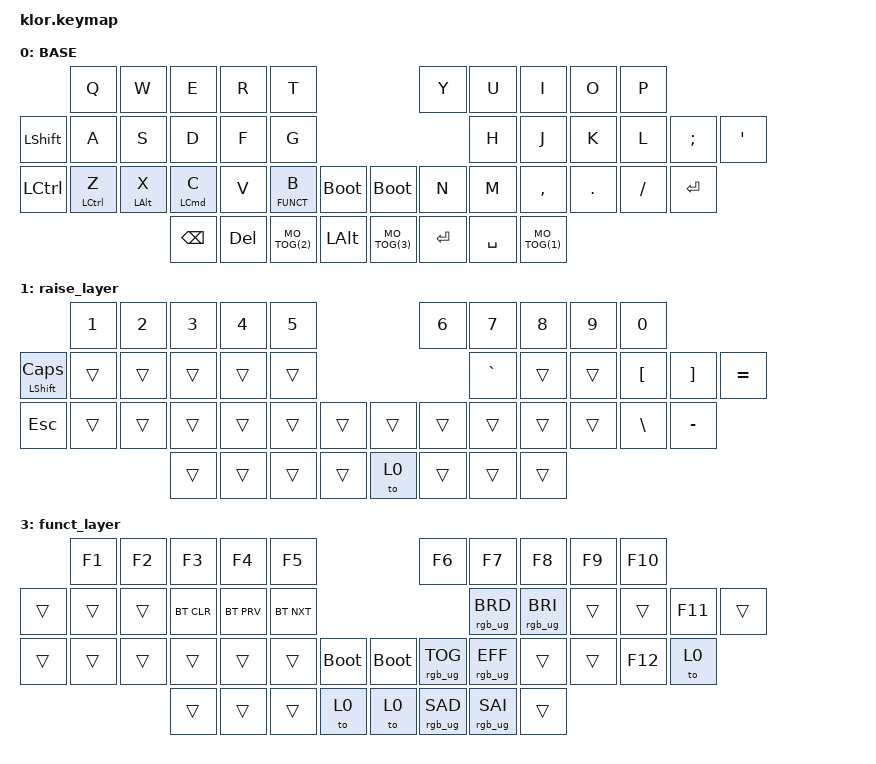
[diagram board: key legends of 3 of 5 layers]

//                               █         █    █            ▄▄▄▀▀▀▀▀▀▄▄▄        █▀▀▀▀▀▀▀▀▀▀█
//                               █        █     █          ▄▀            ▀▄      █          █
//                               █       █      █        ▄▀                ▀▄    █          █
//                               █      █       █        █                  █    █          █
//                               █     █        █       █                    █   █          █
//                               █    █         █       █                    █   █▄▄▄▄▄▄▄▄▄▄█
//                               █   █ █        █       █                    █   █      █
//                               █  █   █       █        █                  █    █       █
//                               █ █     █      █        ▀▄                ▄▀    █        █
//                               ██       █     █          ▀▄            ▄▀      █         █
//                               █         █    █▄▄▄▄▄▄▄▄    ▀▀▀▄▄▄▄▄▄▀▀▀        █          █
//
// ▄▄▄▄▄▄▄▄▄▄▄▄▄▄▄▄▄▄▄▄▄▄▄▄▄▄▄▄▄▄▄▄▄▄▄▄▄▄▄▄▄▄▄▄▄▄▄▄▄▄▄▄▄▄▄▄▄▄▄▄▄▄▄▄▄▄▄▄▄▄▄▄▄▄▄▄▄▄▄▄▄▄▄▄▄▄▄▄▄▄▄▄▄▄▄▄▄▄▄▄▄▄▄▄▄▄▄▄▄▄▄▄▄▄▄▄▄▄▄▄▄▄▄▄▄
       
#include <behaviors.dtsi>
#include <dt-bindings/zmk/keys.h>
#include <dt-bindings/zmk/bt.h>
#include <dt-bindings/zmk/outputs.h>
#include <dt-bindings/zmk/ext_power.h>
#include <dt-bindings/zmk/rgb.h>
#include <dt-bindings/zmk/backlight.h>

#define DEFAULT 0
#define RAISE   1
#define NAVIG   2
#define FUNCT   3
#define NUM     4

#define MO_TOG(layer) &mo_tog layer layer   // Macro to apply momentary-layer-on-hold/toggle-layer-on-tap to a specific layer


/ {
    behaviors {
        hm: homerow_mods {
            compatible = "zmk,behavior-hold-tap";
            label = "HOMEROW_MODS";
            #binding-cells = <2>;
            tapping-term-ms = <150>;
            quick_tap_ms = <0>;
            flavor = "tap-preferred";
            bindings =
                <&kp>,
                <&kp>;
        };
       mo_tog: behavior_mo_tog {
            compatible = "zmk,behavior-hold-tap";
            label = "mo_tog";
            #binding-cells = <2>;
            flavor = "hold-preferred";
            tapping-term-ms = <200>;
            bindings = <&mo>, <&tog>;
        };
       rgb_brightness: rgb_brightness {
            compatible = "zmk,behavior-sensor-rotate";
            label = "RGB_BRIGHTNESS";
            #sensor-binding-cells = <0>;
            bindings = <&rgb_ug RGB_BRD>, <&rgb_ug RGB_BRI>;
        };

      rgb_hue: rgb_hue {
            compatible = "zmk,behavior-sensor-rotate";
            label = "RGB_HUE";
            #sensor-binding-cells = <0>;
            bindings = <&rgb_ug RGB_HUI>, <&rgb_ug RGB_HUD>;
        };

      rgb_saturation: rgb_saturation {
            compatible = "zmk,behavior-sensor-rotate";
            label = "RGB_SATURATION";
            #sensor-binding-cells = <0>;
            bindings = <&rgb_ug RGB_SAD>, <&rgb_ug RGB_SAI>;
        };
      bt_sel: bt_sel {
            compatible = "zmk,behavior-sensor-rotate";
            label = "BT_SEL";
            #sensor-binding-cells = <0>;
            bindings = <&bt BT_NXT>, <&bt BT_PRV>;
        };
    };

combos {
            compatible = "zmk,combos";
     //layers 0
            combo_esc0 {
                timeout-ms = <50>;
                key-positions = <1 2>;
                bindings = <&kp ESC>;
                layers = <0>;
            };
            combo_tab0{
                timeout-ms = <50>;
                key-positions = <11 12>;
                bindings = <&kp TAB>;
                layers = <0>;
             };
       //BS_ENT
            combo_bsp0{
                timeout-ms = <50>;
                key-positions = <16 17>;
                bindings = <&kp BSPC>;
                layers = <0>;
            };
            combo_ent0{
                timeout-ms = <50>;
                key-positions = <17 18>;
                bindings = <&kp ENTER>;
                layers = <0>;
            };
         //Page UP_DN
             combo_pageup0{
                timeout-ms = <50>;
                key-positions = <5 6>;
                bindings = <&kp PG_UP>;
                layers = <0>;
            };
            combo_pagedown0{
                timeout-ms = <50>;
                key-positions = <27 28>;
                bindings = <&kp PG_DN>;
                layers = <0>;
            };
            
      //layers 1
         //BS_ENT
            combo_bsp1{
                timeout-ms = <50>;
                key-positions = <16 17>;
                bindings = <&kp BSPC>;
                layers = <1>;
            };
            combo_ent1{
                timeout-ms = <50>;
                key-positions = <17 18>;
                bindings = <&kp ENTER>;
                layers = <1>;
            };
          //VOLUME_UP_DOWN - BRI_UP_DN
            combo_volup1{
                timeout-ms = <50>;
                key-positions = <5 6>;
                bindings = <&kp C_VOL_UP>;
                layers = <1>;
            };
            combo_voldn1{
                timeout-ms = <50>;
                key-positions = <27 28>;
                bindings = <&kp C_VOL_DN>;
                layers = <1>;
            };
           //BRI_UP_DN
            combo_briup1{
                timeout-ms = <50>;
                key-positions = <13 14>;
                bindings = <&kp C_BRI_DN>;
                layers = <1>;
            };
            combo_bridn1{
                timeout-ms = <50>;
                key-positions = <15 16>;
                bindings = <&kp C_BRI_UP>;
                layers = <1>;
            };
  
            
            
      //layers 2
          //BS_ENT
            combo_bsp2{
                timeout-ms = <50>;
                key-positions = <16 17>;
                bindings = <&kp BSPC>;
                layers = <2>;
            };
            combo_ent2{
                timeout-ms = <50>;
                key-positions = <17 18>;
                bindings = <&kp ENTER>;
                layers = <2>;
            };
    };

    keymap {
        compatible = "zmk,keymap";

// ▄▄▄▄▄▄▄▄▄▄▄▄▄▄▄▄▄▄▄▄▄▄▄▄▄▄▄▄▄▄▄▄▄▄▄▄▄▄▄▄▄▄▄▄▄▄▄▄▄▄▄▄▄▄▄▄▄▄▄▄▄▄▄▄▄▄▄▄▄▄▄▄▄▄▄▄▄▄▄▄▄▄▄▄▄▄▄▄▄▄▄▄▄▄▄▄▄▄▄▄▄▄▄▄▄▄▄▄▄▄▄▄▄▄▄▄▄▄▄▄▄▄▄▄▄▄▄▄▄▄▄▄▄▄▄▄▄▄▄▄▄▄


                base_layer {
// ┌───────────────────────────────────────────────────────────┐
label= "BASE"                                                  ;
// └───────────────────────────────────────────────────────────┘
/*
             ┌─────────┬─────────┬─────────┬─────────┬─────────┐                    ┌─────────┬─────────┬─────────┬─────────┬─────────┐
             │    Q    │    W  {ESC}  E    │    R    │    T    │ ╭╮╭╮╭╮╭╮╭╮╭╮╭╮╭╮╭╮ │    Y  {SCU}  U    │    I    │    O    │    P    │
             ├─────────┼─────────┼─────────┼─────────┼─────────┤ │╰╯╰╯╰╯╰╯╰╯╰╯╰╯╰╯│ ├─────────┼─────────┼─────────┼─────────┼─────────┤
             │    A    │    S    │    D    │    F  {SCL}  G    ├─╯                ╰─┤    H  {SCR}  J  {BSP}  K  {ENT}  L    │    ;    │
             ├─────────┼─────────┼─────────┼─────────┼─────────┤╭────────╮╭────────╮├─────────┼─────────┼─────────┼─────────┼─────────┤
             │ (CTL)Z  │ (ALT)X  │ (CMD)C  │    V    │    B    ││  MUTE  ││PLY/PSE ││    N  {SCD}  M    │    ,    │    .    │    /    │
             └─────────┴─────────┼─────────┼─────────┼─────────┤╰────────╯╰────────╯┼─────────┼─────────┼─────────┼─────────┴─────────┘
                                 │         │ SFT*TAB │ NUM*SPC │                    │ SYM * - │ SFT * ! │         │
                                 └─────────┴─────────┴─────────┘                    └─────────┴─────────┴─────────┘ 
                                 &hm LCTRL A &hm LGUI S &hm LALT D &hm LSHIFT F
                                 */ 
   bindings = <
 //╷         ╷         ╷         ╷         ╷         ╷         ╷         ╷╷         ╷         ╷         ╷         ╷         ╷         ╷         ╷
                &kp Q     &kp W     &kp E     &kp R     &kp T                          &kp Y     &kp U     &kp I     &kp O     &kp P
    &kp LSHIFT  &kp A     &kp S     &kp D     &kp F     &kp G                          &kp H     &kp J     &kp K     &kp L     &kp SEMI  &kp SQT
    &kp LCTRL   &hm LCTRL Z   &hm LALT X   &hm LCMD C   &kp V   &lt FUNCT B   &bootloader   &bootloader   &kp N   &kp M   &kp COMMA   &kp DOT   &kp FSLH   &kp RET
                                 &kp BSPC &kp DEL  MO_TOG(2) &kp LALT   MO_TOG(3)  &kp RET   &kp SPACE  MO_TOG(1)   
                        >;
            sensor-bindings = <&bt_sel &inc_dec_kp C_VOL_UP C_VOL_DN>;
                };
// ▄▄▄▄▄▄▄▄▄▄▄▄▄▄▄▄▄▄▄▄▄▄▄▄▄▄▄▄▄▄▄▄▄▄▄▄▄▄▄▄▄▄▄▄▄▄▄▄▄▄▄▄▄▄▄▄▄▄▄▄▄▄▄▄▄▄▄▄▄▄▄▄▄▄▄▄▄▄▄▄▄▄▄▄▄▄▄▄▄▄▄▄▄▄▄▄▄▄▄▄▄▄▄▄▄▄▄▄▄▄▄▄▄▄▄▄▄▄▄▄▄▄▄▄▄▄▄▄▄▄▄▄▄▄▄▄▄▄▄▄▄▄


                raise_layer {

/*           ┌─────────┬─────────┬─────────┬─────────┬─────────┐                    ┌─────────┬─────────┬─────────┬─────────┬─────────┐
             │    1    │    2    │    3    │    4    │    5    │                    │    6    │    7    │    8    │    9    │    0    │
   ┌─────────┼─────────┼─────────┼─────────┼─────────┼─────────┤                    ├─────────┼─────────┼─────────┼─────────┼─────────┼─────────┐
   │  SCAPS  │         │         │         │         │         │                    │    `    │         │         │    [    │    ]    │    =    │
   ├─────────┼─────────┼─────────┼─────────┼─────────┼─────────┤╭────────╮╭────────╮├─────────┼─────────┼─────────┼─────────┼─────────┼─────────┤
   │   ESC   │         │         │         │         │         ││        ││        ││         │         │         │         │   \ |   │    -    │
   └─────────┴─────────┴─────────┼─────────┼─────────┼─────────┼╰────────╯╰────────╯┼─────────┼─────────┼─────────┼─────────┴─────────┴─────────┘
                                 │         │         │         │         ││   (0)   │         │         │         │  
                                 └─────────┴─────────┴─────────┴─────────┘└─────────┴─────────┴─────────┴─────────┘ */ 
 bindings = <
 //╷         ╷         ╷         ╷         ╷         ╷         ╷         ╷╷         ╷         ╷         ╷         ╷         ╷         ╷         ╷
               &kp N1   &kp N2    &kp N3    &kp N4   &kp N5                            &kp N6   &kp N7    &kp N8    &kp N9    &kp N0
    &mt LSHIFT CLCK  &trans    &trans  &trans  &trans &trans                           &kp GRAVE &trans    &trans  &kp LBKT &kp RBKT    &kp EQUAL
    &kp ESC    &trans   &trans     &trans    &trans   &trans      &trans    &trans     &trans   &trans    &trans    &trans   &kp BSLH  &kp MINUS
                                  &trans    &trans    &trans    &trans     &to 0      &trans   &trans    &trans 
                        >;
            sensor-bindings = <&inc_dec_kp C_VOL_UP C_VOL_DN>;
                };

// ▄▄▄▄▄▄▄▄▄▄▄▄▄▄▄▄▄▄▄▄▄▄▄▄▄▄▄▄▄▄▄▄▄▄▄▄▄▄▄▄▄▄▄▄▄▄▄▄▄▄▄▄▄▄▄▄▄▄▄▄▄▄▄▄▄▄▄▄▄▄▄▄▄▄▄▄▄▄▄▄▄▄▄▄▄▄▄▄▄▄▄▄▄▄▄▄▄▄▄▄▄▄▄▄▄▄▄▄▄▄▄▄▄▄▄▄▄▄▄▄▄▄▄▄▄


                navig_layer {

/*          
             ┌─────────┬─────────┬─────────┬─────────┬─────────┐                    ┌─────────┬─────────┬─────────┬─────────┬─────────┐
             │  ALLCOPY│   SAVE  │   SCRSF │  SCRS   │    +    │ ╭╮╭╮╭╮╭╮╭╮╭╮╭╮╭╮╭╮ │    6 {VOLU}  7    │    8    │    9    │    0    │
             ├─────────┼─────────┼─────────┼─────────┼─────────┤ │╰╯╰╯╰╯╰╯╰╯╰╯╰╯╰╯│ ├─────────┼─────────┼─────────┼─────────┼─────────┤
             │  UNDO   │   CUT   │   COPY  │ PASTE {BRU}  -    ├─╯                ╰─┤    ←  {BRD}  ↑  {BSP}  ↓  {ENT}  →    │    =    │
             ├─────────┼─────────┼─────────┼─────────┼─────────┤╭────────╮╭────────╮├─────────┼─────────┼─────────┼─────────┼─────────┤
             │  CTL    │   ALT   │   CMD   │   SFT   │    *    ││  MUTE  ││PLY/PSE ││    1 {VOLD}  2    │    3    │    4    │    5    │
             └─────────┴─────────┼─────────┼─────────┼─────────┤╰────────╯╰────────╯┼─────────┼─────────┼─────────┼─────────┴─────────┘
                                 │         │    /    │    ▼    │                    │    %    │    .    │         │
                                 └─────────┴─────────┴─────────┘                    └───-─────┴─────────┴─────────┘*/

 bindings = <
 //╷           ╷           ╷           ╷           ╷           ╷           ╷╷           ╷           ╷           ╷           ╷           ╷           ╷
    &kp LG(A)   &kp LG(S)   &sk LG(LS(N3))  &sk LG(LS(N4))  &kp PLUS                     &kp KP_N6   &kp KP_N7   &kp KP_N8   &kp KP_N9   &kp KP_N0
    &kp LG(Z)   &kp LG(X)   &kp LG(C)   &kp LG(V)   &kp MINUS                            &kp LEFT    &kp DOWN    &kp UP      &kp RIGHT   &kp EQUAL
    &kp LCTRL   &kp LALT    &kp LCMD    &kp LSHFT   &kp STAR    &trans        &trans     &kp N1      &kp KP_N2   &kp KP_N3   &kp KP_N4   &kp KP_N5
                            &trans      &kp SLASH   &trans                               &kp PRCNT   &kp DOT     &kp COMMA
                        >;
            sensor-bindings = <&inc_dec_kp C_VOL_UP C_VOL_DN>;
                };

// ▄▄▄▄▄▄▄▄▄▄▄▄▄▄▄▄▄▄▄▄▄▄▄▄▄▄▄▄▄▄▄▄▄▄▄▄▄▄▄▄▄▄▄▄▄▄▄▄▄▄▄▄▄▄▄▄▄▄▄▄▄▄▄▄▄▄▄▄▄▄▄▄▄▄▄▄▄▄▄▄▄▄▄▄▄▄▄▄▄▄▄▄▄▄▄▄▄▄▄▄▄▄▄▄▄▄▄▄▄▄▄▄▄▄▄▄▄▄▄▄▄▄▄▄▄


                funct_layer {

/*           ┌─────────┬─────────┬─────────┬─────────┬─────────┐                    ┌─────────┬─────────┬─────────┬─────────┬─────────┐
             │   F1    │    F2   │    F3   │    F4   │    F5   │                    │   F6    │    F7   │   F8    │   F9    │   F10   │
   ┌─────────┼─────────┼─────────┼─────────┼─────────┼─────────┤                    ├─────────┼─────────┼─────────┼─────────┼─────────┼─────────┐
   │         │         │         │ BT_CLR  | BT_PRV  │ BT_NXT  │                    │         │         │         │         │   F11   │         │
   ├─────────┼─────────┼─────────┼─────────┼─────────┼─────────┤╭────────╮╭────────╮├─────────┼─────────┼─────────┼─────────┼─────────┼─────────┤
   │         │         │         │         │         │         ││  boot  ││  boot  |│ RGB Y/N │ RGB Eff │         │         │   F12   │   (0)   |
   └─────────┴─────────┴─────────┼─────────┼─────────┼─────────┼╰────────╯╰────────╯┼─────────┼─────────┼─────────┼─────────┴─────────┴─────────┘
                                 │         │         │         │   (0)   ││   (0)   │         │         │         │  
                                 └─────────┴─────────┴─────────┴─────────┘└─────────┴─────────┴─────────┴─────────┘ */ 
 bindings = <
 //╷         ╷         ╷         ╷         ╷         ╷         ╷         ╷╷         ╷         ╷         ╷         ╷         ╷         ╷         ╷
               &kp F1    &kp F2    &kp F3    &kp F4     &kp F5                        &kp F6    &kp F7     &kp F8    &kp F9   &kp F10   
    &trans     &trans    &trans    &bt BT_CLR &bt BT_PRV &bt BT_NXT                   &rgb_ug RGB_BRD   &rgb_ug RGB_BRI    &trans    &trans    &kp F11    &trans 
    &trans     &trans    &trans    &trans    &trans   &trans &bootloader  &bootloader  &rgb_ug RGB_TOG &rgb_ug RGB_EFF &trans &trans &kp F12 &to 0    
                                   &trans  &trans     &trans &to 0     &to 0    &rgb_ug RGB_SAD   &rgb_ug RGB_SAI    &trans    
                        >;
            sensor-bindings = <&rgb_hue &rgb_brightness>;
                };
// ▄▄▄▄▄▄▄▄▄▄▄▄▄▄▄▄▄▄▄▄▄▄▄▄▄▄▄▄▄▄▄▄▄▄▄▄▄▄▄▄▄▄▄▄▄▄▄▄▄▄▄▄▄▄▄▄▄▄▄▄▄▄▄▄▄▄▄▄▄▄▄▄▄▄▄▄▄▄▄▄▄▄▄▄▄▄▄▄▄▄▄▄▄▄▄▄▄▄▄▄▄▄▄▄▄▄▄▄▄▄▄▄▄▄▄▄▄▄▄▄▄▄▄▄▄

              num_layer {
// ┌───────────────────────────────────────────────────────────┐
label= "NUM"                                                   ;
// └───────────────────────────────────────────────────────────┘
/*          
             ┌─────────┬─────────┬─────────┬─────────┬─────────┐                    ┌─────────┬─────────┬─────────┬─────────┬─────────┐
             │  ALLCOPY│   SAVE  │   SCRSF │  SCRS   │    +    │ ╭╮╭╮╭╮╭╮╭╮╭╮╭╮╭╮╭╮ │    6 {VOLU}  7    │    8    │    9    │    0    │
             ├─────────┼─────────┼─────────┼─────────┼─────────┤ │╰╯╰╯╰╯╰╯╰╯╰╯╰╯╰╯│ ├─────────┼─────────┼─────────┼─────────┼─────────┤
             │  UNDO   │   CUT   │   COPY  │ PASTE {BRU}  -    ├─╯                ╰─┤    ←  {BRD}  ↑  {BSP}  ↓  {ENT}  →    │    =    │
             ├─────────┼─────────┼─────────┼─────────┼─────────┤╭────────╮╭────────╮├─────────┼─────────┼─────────┼─────────┼─────────┤
             │  CTL    │   ALT   │   CMD   │   SFT   │    *    ││  MUTE  ││PLY/PSE ││    1 {VOLD}  2    │    3    │    4    │    5    │
             └─────────┴─────────┼─────────┼─────────┼─────────┤╰────────╯╰────────╯┼─────────┼─────────┼─────────┼─────────┴─────────┘
                                 │         │    /    │    ▼    │                    │    %    │    .    │         │
                                 └─────────┴─────────┴─────────┘                    └───-─────┴─────────┴─────────┘*/

 bindings = <
 //       ╷           ╷           ╷           ╷           ╷           ╷           ╷╷           ╷           ╷           ╷           ╷           ╷           ╷
              &kp N1      &kp N2      &kp N3      &kp N4      &kp N5                               &kp N6      &kp N7      &kp N8      &kp N9      &kp N0
    &trans    &kp LG(Z)   &kp LG(X)   &kp LG(C)   &kp LG(V)   &kp MINUS                            &kp LEFT    &kp DOWN    &kp UP      &kp RIGHT   &kp EQUAL   &trans
    &trans    &kp LCTRL   &kp LALT    &kp LCMD    &kp LSHFT   &kp STAR    &trans        &trans     &kp N1      &kp KP_N2   &kp KP_N3   &kp KP_N4   &kp KP_N5   &trans
                                      &trans      &kp SLASH   &trans      &trans        &trans     &trans      &kp PRCNT   &kp DOT     &kp COMMA
                        >;
            sensor-bindings = <&inc_dec_kp C_VOL_UP C_VOL_DN>;
                };
        };
};
